VERSION ""

NS_ :

BS_:

BU_: MASTER SENSOR GEO ANDROID MOTOR

BO_ 100 KILL_ALL: 1 ANDROID
 SG_ KILLAllBOARDS : 0|1@1+ (1,0) [0|0] "" MOTOR,MASTER,GEO,SENSOR

BO_ 110 START_STOP: 1 ANDROID
 SG_ START_STOP_CAR : 0|1@1+ (1,0) [0|0] "" MASTER

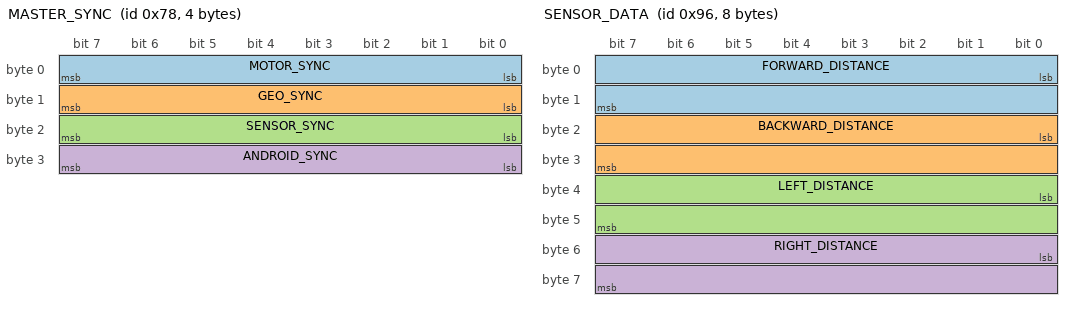
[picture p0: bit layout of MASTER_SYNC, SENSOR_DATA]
BO_ 120 MASTER_SYNC: 4 MASTER
 SG_ MOTOR_SYNC : 0|8@1+ (1,0) [0|0] "" MOTOR,GEO,SENSOR,ANDROID
 SG_ GEO_SYNC : 8|8@1+ (1,0) [0|0] "" MOTOR,GEO,SENSOR,ANDROID
 SG_ SENSOR_SYNC : 16|8@1+ (1,0) [0|0] "" MOTOR,GEO,SENSOR,ANDROID
 SG_ ANDROID_SYNC : 24|8@1+ (1,0) [0|0] "" MOTOR,GEO,SENSOR,ANDROID

BO_ 130 DESTINATION: 8 ANDROID
 SG_ FINAL_LATITUDE : 0|28@1+ (0.000001,-90.000000) [-90|90] "Degrees" MASTER,MOTOR,GEO
 SG_ FINAL_LONGITUDE : 28|29@1+ (0.000001,-180.000000) [-180|180] "Degrees" MASTER,MOTOR,GEO

BO_ 140 CAR_STEER: 2 MASTER
 SG_ WHEELS_SPEED : 0|8@1+ (1,0) [0|0] "" MOTOR
 SG_ WHEELS_STEER : 8|4@1+ (1,0) [0|0] "" MOTOR

BO_ 150 SENSOR_DATA: 8 SENSOR
 SG_ FORWARD_DISTANCE : 0|16@1+ (1,0) [0|0] "Inches" MASTER,MOTOR
 SG_ BACKWARD_DISTANCE : 16|16@1+ (1,0) [0|0] "Inches" MASTER,MOTOR
 SG_ LEFT_DISTANCE : 32|16@1+ (1,0) [0|0] "Inches" MASTER,MOTOR
 SG_ RIGHT_DISTANCE : 48|16@1+ (1,0) [0|0] "Inches" MASTER,MOTOR

BO_ 160 GPS_DATA: 8 GEO
 SG_ GPS_LATITUDE : 0|28@1+ (0.000001,-90.000000) [-90|90] "Degrees" MASTER,MOTOR,ANDROID
 SG_ GPS_LONGITUDE : 28|29@1+ (0.000001,-180.000000) [-180|180] "Degrees" MASTER,MOTOR,ANDROID

BO_ 170 COMPASS: 8 GEO
 SG_ CMP_HEADING : 0|32@1+ (1,0) [0|0] "Degrees" MASTER,MOTOR,ANDROID
 SG_ CMP_BEARING : 32|32@1+ (1,0) [0|0] "Degrees" MASTER,MOTOR,ANDROID

BO_ 180 MOTOR_DATA: 2 MOTOR
 SG_ CAR_SPEED : 0|16@1+ (1,0) [0|0] "" MASTER

CM_ BU_ MASTER "Master controller is heart of the system and will control other boards";
CM_ BU_ MOTOR "Motor will drive the wheels of car and display data on LCD";
CM_ BU_ SENSOR "Sensor will help in obstacle detection and avoidance";
CM_ BU_ GEO "Geo will help in navigation";
CM_ BU_ ANDROID "User sets destination and commands to start-stop the car";
